# J7AEP_GPU_BXS464_WRAP0_GPU_SS_0_CORE_MMRS register map
Vendor: Texas Instruments
Peripheral module from a debugger description file (folder J7_AHP).
Registers are 64-bit, access per field, reset 0x0 unless marked. A register's access mark holds for its fields unless they carry their own. Offsets are as the file gives them; lines under a group give offsets from that group; [hi:lo] are bit positions; {n}, {i} and the like mark numbered series; 'fields as' and 'values as' point back to an identical list; <NAME> marks a mode.

## J7AEP_GPU_BXS464_WRAP0_GPU_SS_0_CORE_MMRS (part 1 of 4)
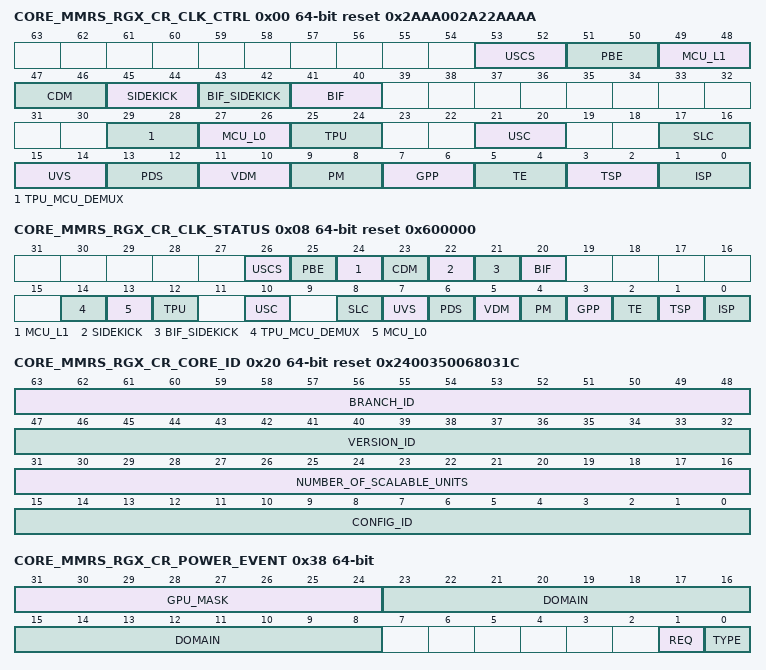
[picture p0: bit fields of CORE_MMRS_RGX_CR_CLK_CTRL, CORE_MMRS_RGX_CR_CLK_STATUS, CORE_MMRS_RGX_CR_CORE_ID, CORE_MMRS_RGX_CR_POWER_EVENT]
0x00 CORE_MMRS_RGX_CR_CLK_CTRL reset 0x2AAA002A22AAAA
  [53:52] USCS rw, [51:50] PBE rw, [49:48] MCU_L1 rw, [47:46] CDM rw, [45:44] SIDEKICK rw, [43:42] BIF_SIDEKICK rw, [41:40] BIF rw, [29:28] TPU_MCU_DEMUX rw, [27:26] MCU_L0 rw, [25:24] TPU rw, [21:20] USC rw, [17:16] SLC rw, [15:14] UVS rw, [13:12] PDS rw, [11:10] VDM rw, [9:8] PM rw, [7:6] GPP rw, [5:4] TE rw, [3:2] TSP rw, [1:0] ISP rw
0x08 CORE_MMRS_RGX_CR_CLK_STATUS ro reset 0x600000
  [26] USCS, [25] PBE, [24] MCU_L1, [23] CDM, [22] SIDEKICK, [21] BIF_SIDEKICK, [20] BIF, [14] TPU_MCU_DEMUX, [13] MCU_L0, [12] TPU, [10] USC, [8] SLC, [7] UVS, [6] PDS, [5] VDM, [4] PM, [3] GPP, [2] TE, [1] TSP, [0] ISP
0x18 CORE_MMRS_RGX_CR_PRODUCT_ID ro reset 0x8470000
  [31:16] IMG_PRODUCT_ID
0x20 CORE_MMRS_RGX_CR_CORE_ID ro reset 0x2400350068031C
  [63:48] BRANCH_ID — B - Branch ID
  [47:32] VERSION_ID — V - Version ID
  [31:16] NUMBER_OF_SCALABLE_UNITS — N - Number of scalable Units
  [15:0] CONFIG_ID — C - Config ID
0x28 CORE_MMRS_RGX_CR_CORE_IP_INTEGRATOR_ID ro
  [31:0] VALUE — IP company ID/Designer
0x30 CORE_MMRS_RGX_CR_CORE_IP_CHANGELIST ro
  [31:0] VALUE — Version control ID
0x38 CORE_MMRS_RGX_CR_POWER_EVENT
  [31:24] GPU_MASK rw — One bit per GPU indicating which GPUs are considered for the power event.
  [23:8] DOMAIN rw — sets which power island is enabled for the current power event request; bit0:jones, bit1-8:dusts, bit9-12:blackpearls
  [1] REQ rw — Set when a power event operation is requested
  [0] TYPE rw — The requested power event operation
0x50 CORE_MMRS_RGX_CR_DUSTS_ENABLE ro reset 0xFF
  [7:0] ENABLE — Dusts enabled
0x58 CORE_MMRS_RGX_CR_DUSTS_FUSE ro reset 0xFF
  [7:0] ENABLE — Dusts enabled
0x80 CORE_MMRS_RGX_CR_CLK_XTPLUS_CTRL reset 0x800000000
  [35:34] ASTC rw
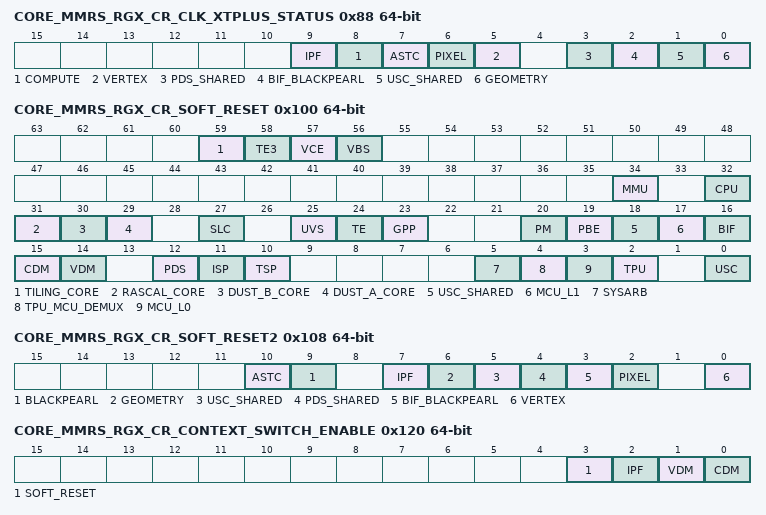
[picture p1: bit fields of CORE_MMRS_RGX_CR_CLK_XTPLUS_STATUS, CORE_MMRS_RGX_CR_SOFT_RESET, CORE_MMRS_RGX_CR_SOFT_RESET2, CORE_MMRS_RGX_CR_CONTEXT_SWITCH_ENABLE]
0x88 CORE_MMRS_RGX_CR_CLK_XTPLUS_STATUS ro
  [9] IPF, [8] COMPUTE, [7] ASTC, [6] PIXEL, [5] VERTEX, [3] PDS_SHARED, [2] BIF_BLACKPEARL, [1] USC_SHARED, [0] GEOMETRY
0xE0 CORE_MMRS_RGX_CR_SOC_TIMER_GRAY ro
  [63:0] VALUE
0xE8 CORE_MMRS_RGX_CR_SOC_TIMER_BINARY ro
  [63:0] VALUE
0x100 CORE_MMRS_RGX_CR_SOFT_RESET
  [59] TILING_CORE ro
  [58] TE3 ro
  [57] VCE ro
  [56] VBS ro
  [34] MMU rw
  [32] CPU rw — Includes MTS and META or MIPS
  [31] RASCAL_CORE rw — Note that the RASL_CORE bit affects logic related to the reading and writing of registers. This soft reset should therefore be used with caution. Upon power down events it is necessary to reset every register, so this bit should be used, but it must be release before any other resets, or beofre anyu other registers are programmed
  [30] DUST_B_CORE rw
  [29] DUST_A_CORE rw
  [27] SLC rw
  [25] UVS rw
  [24] TE rw
  [23] GPP rw
  [20] PM rw
  [19] PBE rw
  [18] USC_SHARED rw
  [17] MCU_L1 rw
  [16] BIF rw — Bifpmcache BIF
  [15] CDM rw
  [14] VDM rw
  [12] PDS rw
  [11] ISP rw
  [10] TSP rw
  [5] SYSARB rw
  [4] TPU_MCU_DEMUX rw
  [3] MCU_L0 rw
  [2] TPU rw
  [0] USC rw
0x108 CORE_MMRS_RGX_CR_SOFT_RESET2
  [10] ASTC rw, [9] BLACKPEARL ro, [7] IPF ro, [6] GEOMETRY ro, [5] USC_SHARED ro, [4] PDS_SHARED ro, [3] BIF_BLACKPEARL ro, [2] PIXEL ro, [0] VERTEX ro
0x120 CORE_MMRS_RGX_CR_CONTEXT_SWITCH_ENABLE
  [3] SOFT_RESET rw, [2] IPF rw, [1] VDM rw, [0] CDM rw
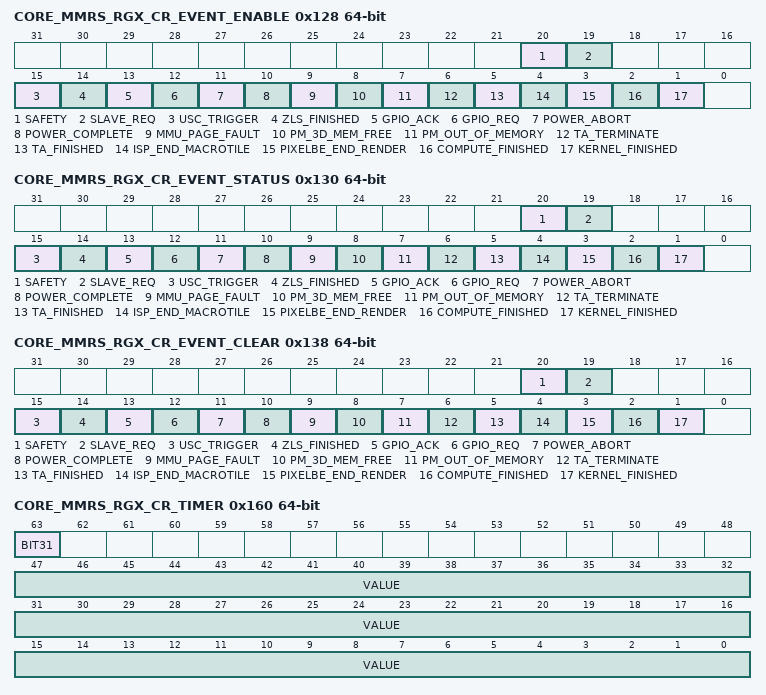
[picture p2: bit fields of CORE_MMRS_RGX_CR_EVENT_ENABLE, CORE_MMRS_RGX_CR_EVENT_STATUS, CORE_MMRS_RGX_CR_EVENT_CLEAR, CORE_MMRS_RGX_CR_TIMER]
0x128 CORE_MMRS_RGX_CR_EVENT_ENABLE
  [20] SAFETY rw — Indicates an interrupt event from an active safety feature has been received
  [19] SLAVE_REQ rw — Indicates an interrupt event from a slave has been received.
  [15] USC_TRIGGER rw — One or more USC has executed a nop.trigger instruction
  [14] ZLS_FINISHED rw — ZLS has finished all tiles in a Render
  [13] GPIO_ACK rw — General Purpose ouput acknowledgement
  [12] GPIO_REQ rw — General Purpose input request
  [11] POWER_ABORT rw — The requested power operation has been denied.
  [10] POWER_COMPLETE rw — The requested power operation has completed
  [9] MMU_PAGE_FAULT rw — An MMU page fault has occurred
  [8] PM_3D_MEM_FREE rw — PM memory allocation completed for the current render
  [7] PM_OUT_OF_MEMORY rw — PM memory allocation failed for a macro-tile
  [6] TA_TERMINATE rw — The TE has aborted a macro tile after a failted PM allocation request
  [5] TA_FINISHED rw — The TA phase has completed
  [4] ISP_END_MACROTILE rw — ISP End-of-Macrotile
  [3] PIXELBE_END_RENDER rw — The 3D phase has completed
  [2] COMPUTE_FINISHED rw — The compute phase has completed
  [1] KERNEL_FINISHED rw — A compute kernel has completed and updated the associated event object in external memory
0x130 CORE_MMRS_RGX_CR_EVENT_STATUS
  fields as CORE_MMRS_RGX_CR_EVENT_ENABLE
0x138 CORE_MMRS_RGX_CR_EVENT_CLEAR
  [20] SAFETY wo — Indicates an interrupt event from an active safety feature has been received
  [19] SLAVE_REQ wo — Indicates an interrupt event from a slave has been received.
  [15] USC_TRIGGER wo — One or more USC has executed a nop.trigger instruction
  [14] ZLS_FINISHED wo — ZLS has finished all tiles in a Render
  [13] GPIO_ACK wo — General Purpose ouput acknowledgement
  [12] GPIO_REQ wo — General Purpose input request
  [11] POWER_ABORT wo — The requested power operation has been denied.
  [10] POWER_COMPLETE wo — The requested power operation has completed
  [9] MMU_PAGE_FAULT wo — An MMU page fault has occurred
  [8] PM_3D_MEM_FREE wo — PM memory allocation completed for the current render
  [7] PM_OUT_OF_MEMORY wo — PM memory allocation failed for a macro-tile
  [6] TA_TERMINATE wo — The TE has aborted a macro tile after a failted PM allocation request
  [5] TA_FINISHED wo — The TA phase has completed
  [4] ISP_END_MACROTILE wo — ISP End-of-Macrotile
  [3] PIXELBE_END_RENDER wo — The 3D phase has completed
  [2] COMPUTE_FINISHED wo — The compute phase has completed
  [1] KERNEL_FINISHED wo — A compute kernel has completed and updated the associated event object in external memory
0x140 CORE_MMRS_RGX_CR_GPIO_OUTPUT_DATA
  [7:0] DATA rw — The data the firmware wants to transfer
0x148 CORE_MMRS_RGX_CR_GPIO_OUTPUT_REQ
  [0] REQ rw — Set when the firmware wants to communicate with a external HW
0x150 CORE_MMRS_RGX_CR_GPIO_INPUT_DATA ro
  [7:0] DATA — The incoming data from HW external to Rogue
0x158 CORE_MMRS_RGX_CR_GPIO_INPUT_ACK
  [0] ACK rw — Set by the firmware when it has acknowledged the incoming request
0x160 CORE_MMRS_RGX_CR_TIMER ro
  [63] BIT31, [47:0] VALUE
0x168 CORE_MMRS_RGX_CR_AXI_EXACCESS
  [0] SOCIF_ENABLE rw — enable the exclusive access logic in the socif img_axi2img. vhd module
0x190 CORE_MMRS_RGX_CR_PM_TASK_MLIST_LOAD
  [0] PENDING wo — A write to this register will cause the MLIST pointer to be loaded from either PM_MLIST0_START_OF or PM_MLIST1_START_OF, depending upon the Context ID contained in PM_CONTEXT_ID_MLS_LS. A read to this register return '1' until this operation has completed.
0x198 CORE_MMRS_RGX_CR_PM_TASK_MLIST_CLEAR
  [0] PENDING wo — A write to this register will cause the MLIST pointer to be reset to 0. A read to this register return '1' until this operation has completed.
0x1A0 CORE_MMRS_RGX_CR_PM_TA_MAX_RENDER_TARGET
  [10:0] ID rw — If used, the software should program this with the maximum render target array index used within the Scene
0x1A8 CORE_MMRS_RGX_CR_PM_MTILE_ARRAY_REORDER_VALID_STATUS ro
  [0] OP
0x1B0 CORE_MMRS_RGX_CR_PM_EMPTY_PAGE_FAST_FREEING reset 0x1
  [0] ID rw — When set, enable freeing of unused pages during TA phase
0x1B8 CORE_MMRS_RGX_CR_PM_MMU_REMAP_PENDING
  [0] OP wo — Pending status register corresponding to the MMU remapping operation, it will become '1' when written and deassert when the operation complete.
0x1C0 CORE_MMRS_RGX_CR_PM_PBE_FORCE_FREEING reset 0x1
  [0] ENABLE rw — When this bit is set, PM will free all the 3D context Memory when a genuine pixelbe end of render is received.
0x1C8 CORE_MMRS_RGX_CR_PM_PDS_STARTOF_MTILEFREE
  [16:0] OP rw — This startof register indicates the macrotile number of the PDSs current macrotile free request, needs to be programmed by FW on a render start
0x200 CORE_MMRS_RGX_CR_PM_TASK_3D_FREE_LOAD
  [0] PENDING wo — A write into this register will cause the 3D free list context to be loaded from the relevant configuration registers
0x208 CORE_MMRS_RGX_CR_PM_TASK_TA_FREE_LOAD
  [0] PENDING wo — A write into this register will cause the TA free list context to be loaded from the relevant configuration registers
0x210 CORE_MMRS_RGX_CR_PM_TA_FSTACK_BASE
  [39:4] ADDR rw — 1TB Addressable, 128 bits aligned Base Address for TA context page tables in the DPM module
0x218 CORE_MMRS_RGX_CR_PM_3D_FSTACK_BASE
  [39:4] ADDR rw — 1TB Addressable, 128 bits aligned Base Address for 3D context page tables in the DPM module
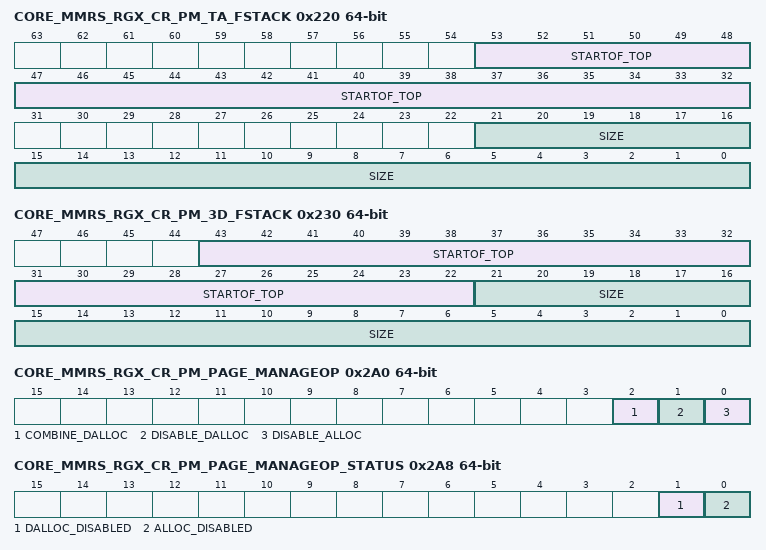
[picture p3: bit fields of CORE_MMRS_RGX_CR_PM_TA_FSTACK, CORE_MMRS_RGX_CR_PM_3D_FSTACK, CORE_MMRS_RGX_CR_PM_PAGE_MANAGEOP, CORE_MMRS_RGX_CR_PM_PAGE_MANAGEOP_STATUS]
0x220 CORE_MMRS_RGX_CR_PM_TA_FSTACK
  [53:32] STARTOF_TOP rw — This register defines the head pointer of the free list in terms of 4K free pages in the free list stack, effective on a load TA context.
  [21:0] SIZE rw — This register defines the number of 4K pages in the free list stack used for the TA page allocation, effective on a load TA context.
0x230 CORE_MMRS_RGX_CR_PM_3D_FSTACK
  [43:22] STARTOF_TOP rw — This register defines the head pointer of the free list in terms of 4K free pages in the free list stack, effective on a load TA context.
  [21:0] SIZE rw — This register defines the number of 4K pages in the free list stack used for the TA page allocation, effective on a load TA context.
0x240 CORE_MMRS_RGX_CR_PM_MTILE_ARRAY
  [39:4] BASE_ADDR rw — 1TB Addressable, 128 bits aligned Base Address for Mtile Array Base
0x248 CORE_MMRS_RGX_CR_PM_VHEAP_TABLE
  [39:4] BASE_ADDR rw — 1TB Addressable, 128 bits aligned Base Address for Virtual Heap Table
0x250 CORE_MMRS_RGX_CR_PM_TASK_VHEAP_LOAD
  [0] PENDING rw — Causes the vheap to be loaded as specified by the relevant configuration registers, when it is done the hw will clear this bit
0x258 CORE_MMRS_RGX_CR_PM_TASK_VHEAP_CLEAR
  [0] PENDING rw — Causes the vheap to be cleared as specified by the relevant configuration registers. When it is done, the hw will clear this bit
0x260 CORE_MMRS_RGX_CR_PM_TASK_VHEAP_STORE
  [0] PENDING rw — Causes the vheap to be stored as specified by the relevant configuration registers. When it is done, the hw will clear this bit
0x268 CORE_MMRS_RGX_CR_PM_ALIST0_START_OF
  [32:0] TAIL rw — allocation List 0 tail pointer
0x270 CORE_MMRS_RGX_CR_PM_ALIST0_STATUS ro
  [32:0] TAIL — allocation List tail pointer
0x278 CORE_MMRS_RGX_CR_PM_ALIST1_START_OF
  [32:0] TAIL rw — start of the allocation list tail pointer
0x280 CORE_MMRS_RGX_CR_PM_ALIST1_STATUS ro
  [32:0] TAIL — allocation List tail pointer
0x288 CORE_MMRS_RGX_CR_PM_TASK_ALIST_LOAD
  [0] PENDING wo — the write to this register will cause allocation list to be loaded from the relevant configuration registers
0x290 CORE_MMRS_RGX_CR_PM_TASK_ALIST_CLEAR
  [0] PENDING wo — the write to this register will causes the allocation list to be cleard from the relevant configuration registers
0x298 CORE_MMRS_RGX_CR_PM_DEALLOCATION_STARTOF_MASK
  [15:0] OP rw — This is the start of the mask PM deallocation will be based on. Normally, it is 0. However, in ISP context resume or extra 3D timeout case, the driver has to programme the value from the previous render.
0x2A0 CORE_MMRS_RGX_CR_PM_PAGE_MANAGEOP
  [2] COMBINE_DALLOC rw — 1 means the PM writes to the free stack will be burst combined
  [1] DISABLE_DALLOC rw — 1 means the PM page management deallocation operation will be disabled
  [0] DISABLE_ALLOC rw — 1 means the PM page management allocation operation will be disabled
0x2A8 CORE_MMRS_RGX_CR_PM_PAGE_MANAGEOP_STATUS ro
  [1] DALLOC_DISABLED — 1 means the PM page management operation has been disabled
  [0] ALLOC_DISABLED — 1 means the PM page management operation has been disabled
0x2B0 CORE_MMRS_RGX_CR_PM_CONTEXT_PB_BASE
  [2:0] CMP rw — Defines whether the TA/3D/HOST contexts are using the same parameter buffer. Setting a bit to '1' indicates that the context is using a different parameter buffer. Bit 0 = 0 : Unified Free List 3D context Parameter buffer = Unified Free List TA context Parameter buffer Bit 1 = 0 : 3D context parameter buffer = TA context parameter buffer Bit 2 = 0 : MMU Free List 3D context Parameter buffer = MMU Free List TA context Parameter buffer[this is a per context resource, so it should be the same with bit 1
0x2B8 CORE_MMRS_RGX_CR_PM_MLIST0_START_OF
  [21:0] TAIL rw — allocation List 0 tail pointer
0x2C0 CORE_MMRS_RGX_CR_PM_MLIST0_STATUS ro
  [21:0] TAIL — allocation List 1 tail pointer
0x2C8 CORE_MMRS_RGX_CR_PM_MLIST1_START_OF
  [21:0] TAIL rw — start of the allocation list 1 tail pointer
0x2D0 CORE_MMRS_RGX_CR_PM_MLIST1_STATUS ro
  [21:0] TAIL — mmu allocation List 1 tail pointer
0x2D8 CORE_MMRS_RGX_CR_PM_MLIST0_BASE
  [39:4] ADDR rw — 1TB Addressable, 128 bits aligned Base Address for mmu list0 module, Effective Immediately
0x2E0 CORE_MMRS_RGX_CR_PM_MLIST1_BASE
  [39:4] ADDR rw — 1TB Addressable, 128 bits aligned Base Address for mmu list1 module, Effective Immediately
0x2F8 CORE_MMRS_RGX_CR_PM_VCE_VTOP_STATUS ro
  [20:0] OP — Virtual Page Pointer for the VCE, 8KB granularity
0x300 CORE_MMRS_RGX_CR_PM_TE_VTOP_STATUS ro
  [20:0] OP — Virtual Page Pointer for the TE, 8KB granularity
0x308 CORE_MMRS_RGX_CR_PM_OUTOF_MEM_SRC ro
  [2:0] OP — one hot encoding indicating which part of resource runs out of memory bit 0: normal ta free list, bit 1: unified ta free list, bit 2: mmu free list
0x310 CORE_MMRS_RGX_CR_PM_ALIST_VTOP_STATUS ro
  [20:0] OP — Virtual Page Pointer for the allocation list, 8KB granularity
0x318 CORE_MMRS_RGX_CR_PM_MMU_VTOP_STATUS ro
  [20:0] OP — Virtual Page Pointer for the MMU, 4KB granularity
0x320 CORE_MMRS_RGX_CR_PM_OUTOFMEM_ABORTALL
  [0] OP wo — Instruct the PM to Deny the TE allocation outstanding on Out Of Memory
0x328 CORE_MMRS_RGX_CR_PM_OUTOFMEM_RESTART
  [0] OP wo — Restart the PM after an Out of Memory and Abort sequence
0x330 CORE_MMRS_RGX_CR_PM_REQUESTING_SOURCE ro
  [1:0] OP — Requesting source when out of memory. Bit 1 : VCE, Bit 0 : TE
0x338 CORE_MMRS_RGX_CR_PM_PARTIAL_RENDER_ENABLE
  [0] OP rw — Partial Render Enable Bit
0x340 CORE_MMRS_RGX_CR_PM_3D_DEALLOCATE_SCANMODE
  [4:0] OP rw — This register defines the deallocation behaviour of the PM: value > 2 is only for debug, on ZLS mode 0, it can only set less than 2 0: PM will free the macrotile memory as soon as it is possible 1: PM only free one mtile for each traverse 2: PM only free two mtiles for each traverse ... 16: PM only free 16 mtiles for each traverse. Other Value are all invalid values
0x348 CORE_MMRS_RGX_CR_PM_TA_FSTACK_STATUS ro
  [21:0] TOP — This status register indicated the ta context free list pointer status.
0x350 CORE_MMRS_RGX_CR_PM_3D_FSTACK_STATUS ro
  [21:0] TOP — This status register indicated the 3D context free list status
0x358 CORE_MMRS_RGX_CR_PM_RESERVE_PAGES reset 0x5
  [15:0] OP rw — This register defines the guard page required for one VCE/TE allocation. The requirement is set by the number of ppages needed to create the ALIST nodes when a vpage is closed. The MMU requirement is fixed at 3 ppages max for creatig a new ALIST mapping. The rest of the guarding is formed of the amount of ALIST space needed to form the maximum number of nodes a vpage could need. This is defined by the number of RTAs that could be present in a vpage. In all cores, the amount of ALIST space needed doesn't exceed 1 ppage. However the ALIST is allocated at vpage granularity so this needs to be rounded up to a vpage size in ppages. With a vpage size of 16KB or 4*4KB the requirement is 4 ppages and the TOTAL = 3+4 meaning a register setting of 0x7 is required. With a vpage size of 8KB or 2*4Kb the requirement is 2 ppages and the TOTAL = 3+2 meaning a register setting of 0x5 is required.
0x360 CORE_MMRS_RGX_CR_PM_DEALLOCATED_MASK_STATUS ro
  [15:0] TOP — This status register contains a bitmask of the macrotiles freed at this point in the render
0x368 CORE_MMRS_RGX_CR_PM_DEALLOCATING_MASK_STATUS ro
  [15:0] TOP — This status register indicates the mtile mask being freed at the current traverse
0x370 CORE_MMRS_RGX_CR_PM_PDS_MTILEFREE_STATUS ro
  [16:0] OP — This status register indicates the macrotile number of the PDSs current macrotile free request
0x378 CORE_MMRS_RGX_CR_PM_TA_FREE_CONTEXT
  [0] PENDING rw — free the ta context register operation
0x380 CORE_MMRS_RGX_CR_PM_3D_TIMEOUT_NOW
  [0] OP wo — free the 3D context
0x388 CORE_MMRS_RGX_CR_PM_3D_DEALLOCATE_ENABLE reset 0x1
  [0] OP rw — 3D deallocate enable mode
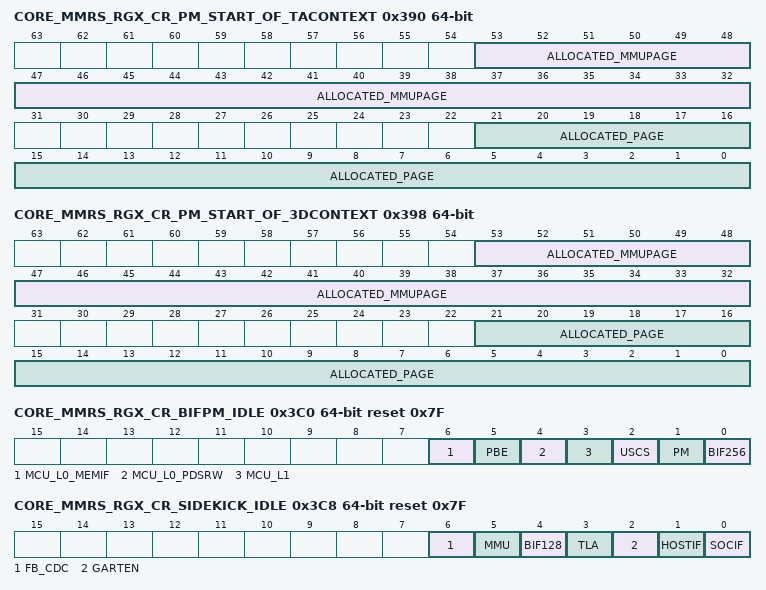
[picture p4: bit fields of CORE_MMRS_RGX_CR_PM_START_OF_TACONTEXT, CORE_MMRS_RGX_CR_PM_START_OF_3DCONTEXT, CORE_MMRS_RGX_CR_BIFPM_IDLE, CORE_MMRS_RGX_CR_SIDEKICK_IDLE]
0x390 CORE_MMRS_RGX_CR_PM_START_OF_TACONTEXT
  [53:32] ALLOCATED_MMUPAGE rw — Start of TA MMU pages[4KB] on loading of the TA context
  [21:0] ALLOCATED_PAGE rw — Start of TA pages[4KB] on loading of the TA context
0x398 CORE_MMRS_RGX_CR_PM_START_OF_3DCONTEXT
  [53:32] ALLOCATED_MMUPAGE rw — Start of 3D MMU pages[4KB] on loading of the TA context
  [21:0] ALLOCATED_PAGE rw — Start of 3D pages[4KB] on loading of the TA context
0x3A0 CORE_MMRS_RGX_CR_PM_TA_PAGE_STATUS ro
  [21:0] OP — The number of TA pages currently allocated
0x3A8 CORE_MMRS_RGX_CR_PM_3D_PAGE_STATUS ro
  [21:0] OP — The number of 3D pages currently allocated
0x3B0 CORE_MMRS_RGX_CR_PM_VCE_INFLIGHT_STATUS ro
  [20:0] OP — The Virtual Page Number in flight in the VCE Requestor
0x3B8 CORE_MMRS_RGX_CR_PM_TE_INFLIGHT_STATUS ro
  [20:0] OP — The Virtual Page Number in flight in the TE Requestor
0x3C0 CORE_MMRS_RGX_CR_BIFPM_IDLE ro reset 0x7F
  [6] MCU_L0_MEMIF — MCU L0 MEMIF Module IDLE
  [5] PBE — PBE Module IDLE
  [4] MCU_L0_PDSRW — MCU L0 PDSRW Module IDLE
  [3] MCU_L1 — MCU L1 Module IDLE
  [2] USCS — USC Shared Module IDLE
  [1] PM — PM Module IDLE
  [0] BIF256 — BIF256 Module IDLE
0x3C8 CORE_MMRS_RGX_CR_SIDEKICK_IDLE ro reset 0x7F
  [6] FB_CDC — FB CDC Module IDLE
  [5] MMU — MMU Module IDLE
  [4] BIF128 — BIF128 Module IDLE
  [3] TLA — TLA Module IDLE
  [2] GARTEN — GARTEN Module IDLE
  [1] HOSTIF — HOSTIF Module IDLE
  [0] SOCIF — SOCIF Module IDLE
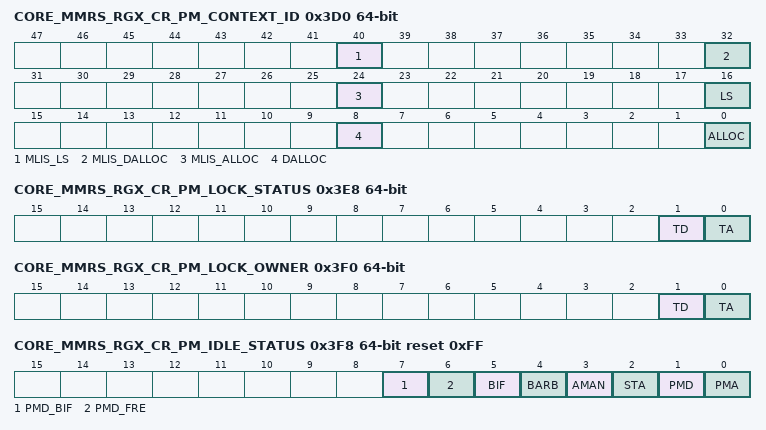
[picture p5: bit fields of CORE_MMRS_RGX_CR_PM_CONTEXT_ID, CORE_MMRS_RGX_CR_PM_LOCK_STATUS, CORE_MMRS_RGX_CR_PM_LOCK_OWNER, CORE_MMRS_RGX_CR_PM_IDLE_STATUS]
0x3D0 CORE_MMRS_RGX_CR_PM_CONTEXT_ID
  [40] MLIS_LS rw — MMU page List [TE,VCE aligned with this context ]Load Store Context ID
  [32] MLIS_DALLOC rw — MMU page List [TE,VCE aligned with this context ]DeAllocation Context ID
  [24] MLIS_ALLOC rw — MMU page List [TE,VCE aligned with this context ]Allocation Context ID
  [16] LS rw — Load Store Context ID for the allocation list
  [8] DALLOC rw — DeAllocation Context ID for the allocation list
  [0] ALLOC rw — Allocation Context ID for the allocation list
0x3D8 CORE_MMRS_RGX_CR_PM_3D_RENDER_TARGET_INDEX
  [10:0] ID rw — Render Target ID which is being rendered
0x3E0 CORE_MMRS_RGX_CR_PM_3D_RENDER_TARGET_LAST reset 0x1
  [0] ID rw — If this bit is set, this means the render will be the last one in the whole render target array. If no multiple render target array is present, this bit always needs set
0x3E8 CORE_MMRS_RGX_CR_PM_LOCK_STATUS ro
  [1] TD — Bit 1: 3D free list Lock Status. 0 idle/ 1 used
  [0] TA — Bit 0: TA free list Lock Status. 0 idle/ 1 used.
0x3F0 CORE_MMRS_RGX_CR_PM_LOCK_OWNER ro
  [1] TD — Bit 1 :3D free list Lock owner. 0 PMA / 1 PMD
  [0] TA — Bit 0: TA free list Lock Owner. 0 PMA / 1 PMD.
0x3F8 CORE_MMRS_RGX_CR_PM_IDLE_STATUS ro reset 0xFF
  [7] PMD_BIF — Idle Status Register of the PMD module bif state machine
  [6] PMD_FRE — Idle Status Register of the PMD module master state machine
  [5] BIF — Idle Status Register of the BIF Interface, default
  [4] BARB — Idle Status Register of the BIF Arbiter state BAR
  [3] AMAN — Idle Status Register of the Alist state machine
  [2] STA — Idle Status Register of the Stack Manager Modul
  [1] PMD — Idle Status Register of the PMD module
  [0] PMA — Idle Status Register of the PMA module
0x400 CORE_MMRS_RGX_CR_VDM_START
  [0] PULSE wo — Start VDM
0x408 CORE_MMRS_RGX_CR_VDM_CTRL_STREAM_BASE
  [39:2] ADDR rw — 1TB range, 32-bit aligned base address
0x410 CORE_MMRS_RGX_CR_VDM_CTRL_STREAM_CURRENT ro
  [39:2] ADDR — 1TB range, 32-bit aligned address
0x418 CORE_MMRS_RGX_CR_VDM_CALL_STACK_POINTER
  [39:3] ADDR rw — 1TB range, 64-bit aligned base address
0x420 CORE_MMRS_RGX_CR_VDM_BATCH
  [13:0] NUMBER rw
0x428 CORE_MMRS_RGX_CR_VDM_CONTEXT_STATE_BASE
  [39:4] ADDR rw — 1TB range, 128-bit aligned base address
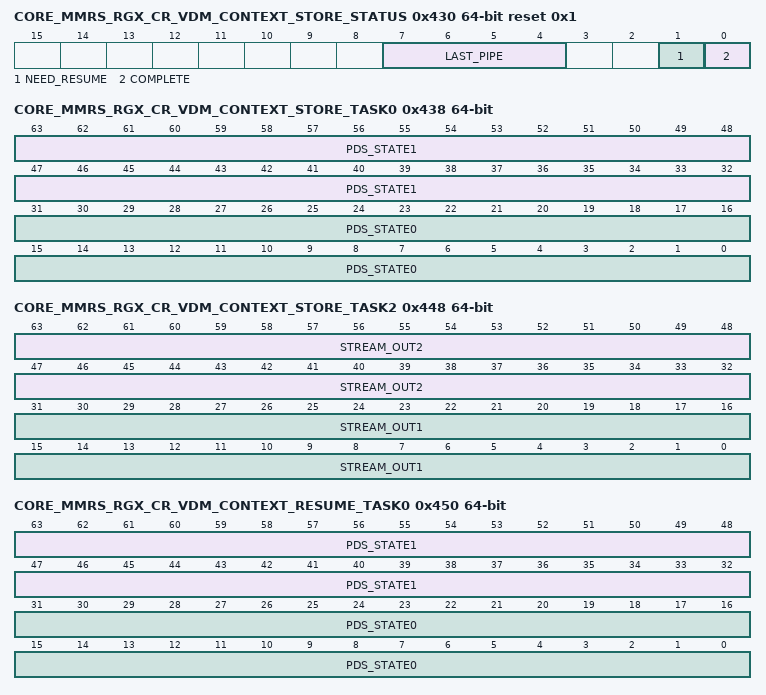
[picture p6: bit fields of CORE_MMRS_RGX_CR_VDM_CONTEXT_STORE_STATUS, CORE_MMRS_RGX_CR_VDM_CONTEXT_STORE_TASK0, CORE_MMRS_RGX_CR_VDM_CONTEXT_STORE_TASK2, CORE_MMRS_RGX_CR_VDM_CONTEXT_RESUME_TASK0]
0x430 CORE_MMRS_RGX_CR_VDM_CONTEXT_STORE_STATUS ro reset 0x1
  [7:4] LAST_PIPE — The TA pipe number to which the VDM last sent indices
  [1] NEED_RESUME — The VDM still has control stream left to process, meaning this context must be resumed
  [0] COMPLETE — The VDM has completed the context store operation and fenced its state to external memory
0x438 CORE_MMRS_RGX_CR_VDM_CONTEXT_STORE_TASK0 rw
  [63:32] PDS_STATE1, [31:0] PDS_STATE0
0x440 CORE_MMRS_RGX_CR_VDM_CONTEXT_STORE_TASK1
  [31:0] PDS_STATE2 rw
0x448 CORE_MMRS_RGX_CR_VDM_CONTEXT_STORE_TASK2 rw
  [63:32] STREAM_OUT2, [31:0] STREAM_OUT1
0x450 CORE_MMRS_RGX_CR_VDM_CONTEXT_RESUME_TASK0 rw
  [63:32] PDS_STATE1, [31:0] PDS_STATE0
0x458 CORE_MMRS_RGX_CR_VDM_CONTEXT_RESUME_TASK1
  [31:0] PDS_STATE2 rw
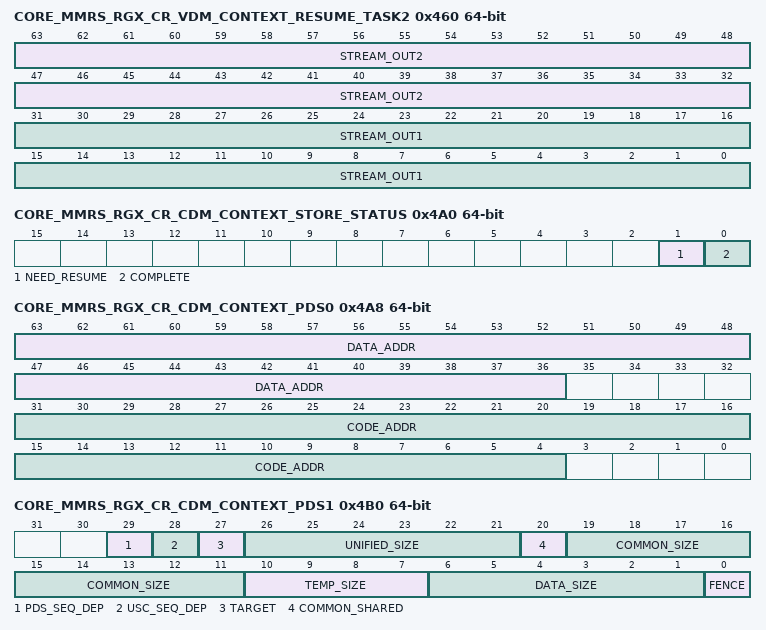
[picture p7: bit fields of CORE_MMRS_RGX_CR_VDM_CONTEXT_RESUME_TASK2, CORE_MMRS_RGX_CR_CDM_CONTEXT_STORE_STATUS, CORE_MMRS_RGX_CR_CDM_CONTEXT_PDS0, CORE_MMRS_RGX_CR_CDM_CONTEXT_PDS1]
0x460 CORE_MMRS_RGX_CR_VDM_CONTEXT_RESUME_TASK2 rw
  [63:32] STREAM_OUT2, [31:0] STREAM_OUT1
0x468 CORE_MMRS_RGX_CR_VDM_CONTEXT_STORE_START
  [0] PULSE wo
0x470 CORE_MMRS_RGX_CR_VDM_SYNC_PDS_DATA_BASE
  [31:4] ADDR rw
0x478 CORE_MMRS_RGX_CR_CDM_START
  [0] PULSE wo — Start CDM
0x480 CORE_MMRS_RGX_CR_CDM_CTRL_STREAM_BASE
  [39:2] ADDR rw — 1TB range, 32-bit aligned base address
0x488 CORE_MMRS_RGX_CR_CDM_CONTEXT_STORE
  [0] PULSE wo
0x490 CORE_MMRS_RGX_CR_CDM_CONTEXT_LOAD
  [0] PENDING wo
0x498 CORE_MMRS_RGX_CR_CDM_CONTEXT_STATE_BASE
  [39:4] ADDR rw — 1TB range, 128-bit aligned base address
0x4A0 CORE_MMRS_RGX_CR_CDM_CONTEXT_STORE_STATUS ro
  [1] NEED_RESUME — The CDM still has control stream left to process, meaning this context must be resumed
  [0] COMPLETE — The CDM has completed the context store operation and fenced its state to external memory
0x4A8 CORE_MMRS_RGX_CR_CDM_CONTEXT_PDS0
  [63:36] DATA_ADDR rw — PDS Data Address for Store/Load Program, 128-bit aligned
  [31:4] CODE_ADDR rw — PDS Code Address for Store/Load Program, 128-bit aligned
0x4B0 CORE_MMRS_RGX_CR_CDM_CONTEXT_PDS1
  [29] PDS_SEQ_DEP rw — PDS Sequential Dependency
  [28] USC_SEQ_DEP rw — USC Sequential Dependency
  [27] TARGET rw — USC Target [0=All, 1=Any]
  [26:21] UNIFIED_SIZE rw
  [20] COMMON_SHARED rw — PDS Common Store Allocation is Shared Registers
  [19:11] COMMON_SIZE rw — PDS Common Size
  [10:7] TEMP_SIZE rw — PDS Temp Size
  [6:1] DATA_SIZE rw — PDS Data Size
  [0] FENCE rw — Fence the Task in the PDS/USC - Set on Store, unset on Load
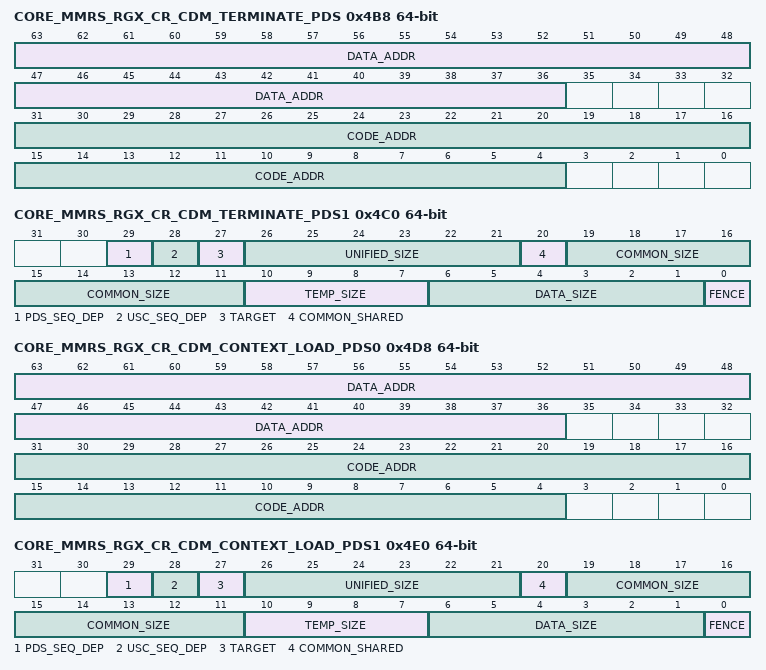
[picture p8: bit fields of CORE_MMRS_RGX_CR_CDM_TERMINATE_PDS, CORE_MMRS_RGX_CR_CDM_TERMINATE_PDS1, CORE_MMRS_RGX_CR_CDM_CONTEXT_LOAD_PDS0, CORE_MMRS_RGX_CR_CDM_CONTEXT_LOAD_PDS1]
0x4B8 CORE_MMRS_RGX_CR_CDM_TERMINATE_PDS
  [63:36] DATA_ADDR rw — PDS Data Address for Terminate Program, 128-bit aligned
  [31:4] CODE_ADDR rw — PDS Code Address for Terminate Program, 128-bit aligned
0x4C0 CORE_MMRS_RGX_CR_CDM_TERMINATE_PDS1
  [29] PDS_SEQ_DEP rw — PDS Sequential Dependency
  [28] USC_SEQ_DEP rw — USC Sequential Dependency
  [27] TARGET rw — USC Target [0=All, 1=Any]
  [26:21] UNIFIED_SIZE rw
  [20] COMMON_SHARED rw — PDS Common Store Allocation is Shared Registers
  [19:11] COMMON_SIZE rw — PDS Common Size
  [10:7] TEMP_SIZE rw — PDS Temp Size
  [6:1] DATA_SIZE rw — PDS Data Size
  [0] FENCE rw — Fence the Task in the PDS/USC - Set on Store Terminate
0x4D8 CORE_MMRS_RGX_CR_CDM_CONTEXT_LOAD_PDS0
  fields as CORE_MMRS_RGX_CR_CDM_CONTEXT_PDS0
0x4E0 CORE_MMRS_RGX_CR_CDM_CONTEXT_LOAD_PDS1
  fields as CORE_MMRS_RGX_CR_CDM_CONTEXT_PDS1
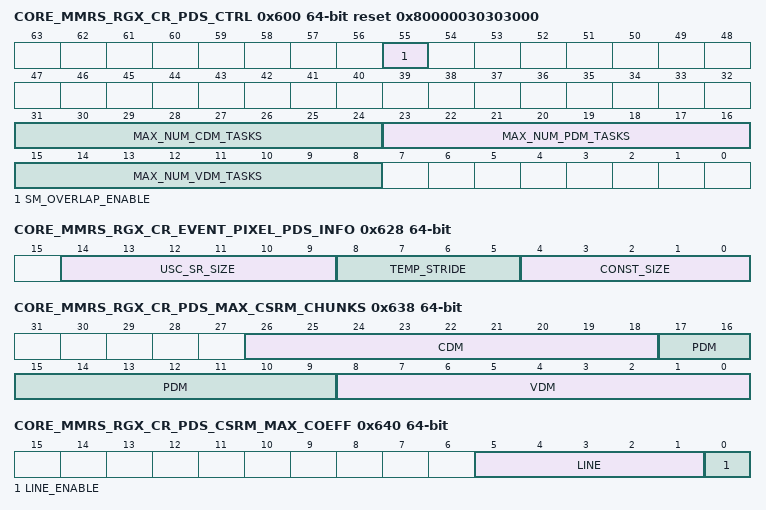
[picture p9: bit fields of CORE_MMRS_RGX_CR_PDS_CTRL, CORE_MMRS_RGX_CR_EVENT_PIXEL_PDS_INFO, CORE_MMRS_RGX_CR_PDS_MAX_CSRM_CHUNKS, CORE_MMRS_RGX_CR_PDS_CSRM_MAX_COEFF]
0x600 CORE_MMRS_RGX_CR_PDS_CTRL reset 0x80000030303000
  [55] SM_OVERLAP_ENABLE rw — Enable per Data Master slot tracking within the PDS Slot Manager [SM] for improved performance while running overlapped
  [31:24] MAX_NUM_CDM_TASKS rw — The maximum number of compute tasks allowed on each USC, range 0 to 48
  [23:16] MAX_NUM_PDM_TASKS rw — The maximum number of pixel tasks allowed on each USC, range 0 to 48
  [15:8] MAX_NUM_VDM_TASKS rw — The maximum number of vertex tasks [VS, HS, GS when Tess not enabled] allowed on each USC, range 0 to 39 [Note reduced range to prevent Pixel/VDM system deadlock]
0x608 CORE_MMRS_RGX_CR_PDS_USC_COLLATOR
  [0] CLEAR wo — Clear PDS Unified Clusters Resource Collator
0x610 CORE_MMRS_RGX_CR_PDS_EXEC_BASE
  [39:20] ADDR rw — 1TB addressable, 1 MB aligned base address for PDS programs
0x618 CORE_MMRS_RGX_CR_EVENT_PIXEL_PDS_CODE
  [31:4] ADDR rw — PDS Execution Address for pixel tasks [Positioned as a byte address, 128 bit granularity], 4 GB Range
0x620 CORE_MMRS_RGX_CR_EVENT_PIXEL_PDS_DATA
  fields as CORE_MMRS_RGX_CR_EVENT_PIXEL_PDS_CODE
0x628 CORE_MMRS_RGX_CR_EVENT_PIXEL_PDS_INFO
  [14:9] USC_SR_SIZE rw — USC Shared Register Data Size in 4x128 bit words [0=0] for pixel event task, if zero pixel event task is skipped
  [8:5] TEMP_STRIDE rw — PDS Temp Size in 128 bit words [0=0] for pixel event tasks
  [4:0] CONST_SIZE rw — PDS Data Size in 128 bit words [0=0] for pixel event tasks, if zero pixel event task is skipped
0x630 CORE_MMRS_RGX_CR_PDS_CSRM
  [0] CLEAR wo — Clear PDS Common Store Resource Manager, a write to this register results in a one cycle pulse
0x638 CORE_MMRS_RGX_CR_PDS_MAX_CSRM_CHUNKS
  [26:18] CDM rw — Max Number of Allocation Regions to Allocate to the Compute Data Master in Common Store
  [17:9] PDM rw — Max Number of Allocation Regions to Allocate to the Pixel Data Master in Common Store
  [8:0] VDM rw — Max Number of Allocation Regions to Allocate to the VDM Data Master in Common Store
0x640 CORE_MMRS_RGX_CR_PDS_CSRM_MAX_COEFF
  [5:1] LINE rw — Coefficients are allocated from Line 0 upwards, this is the maximum Line to use for Coefficients before wrapping
  [0] LINE_ENABLE rw — Enable Max Coefficient Line Limit
0x648 CORE_MMRS_RGX_CR_PDS_USRM
  [0] CLEAR wo — Clear PDS Unified Store Resource Manager, a write to this register results in a one cycle pulse
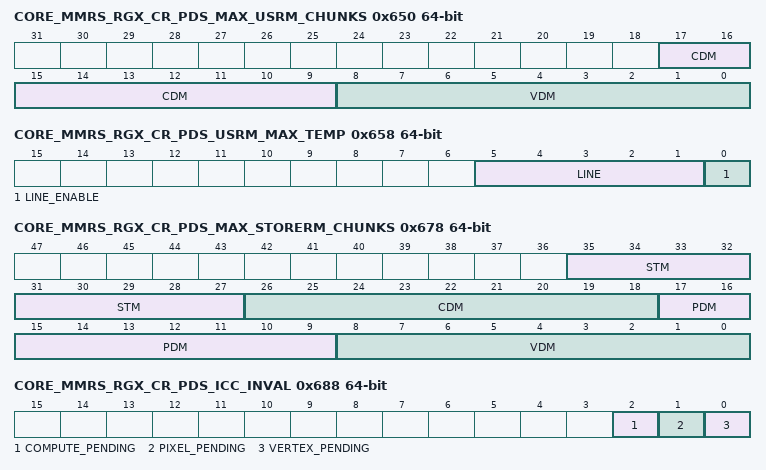
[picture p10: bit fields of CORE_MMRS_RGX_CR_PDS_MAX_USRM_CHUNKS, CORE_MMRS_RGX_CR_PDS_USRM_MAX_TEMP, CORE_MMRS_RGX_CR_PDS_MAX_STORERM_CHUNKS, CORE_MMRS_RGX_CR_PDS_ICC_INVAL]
0x650 CORE_MMRS_RGX_CR_PDS_MAX_USRM_CHUNKS
  [17:9] CDM rw — Max Number of Allocation Regions to Allocate to the Compute Data Master in Unified Store
  [8:0] VDM rw — Max Number of Allocation Regions to Allocate to the VDM Data Master in Unified Store
0x658 CORE_MMRS_RGX_CR_PDS_USRM_MAX_TEMP
  [5:1] LINE rw — Max Line for use as Temporaries
  [0] LINE_ENABLE rw — Enable Max Temporaries Line Limit
0x660 CORE_MMRS_RGX_CR_PDS_UVSRM
  [0] CLEAR wo — Clear PDS Unified Vertex Store Resource Manager, a write to this register results in a one cycle pulse
0x670 CORE_MMRS_RGX_CR_PDS_STORERM
  [0] CLEAR wo — Clear PDS Store Resource Manager, a write to this register results in a one cycle pulse
0x678 CORE_MMRS_RGX_CR_PDS_MAX_STORERM_CHUNKS
  [35:27] STM rw — Max Number of Allocation Regions to Allocate to the Stream Out Data Master in PDS Store
  [26:18] CDM rw — Max Number of Allocation Regions to Allocate to the Compute Data Master in PDS Store
  [17:9] PDM rw — Max Number of Allocation Regions to Allocate to the Pixel Data Master in PDS Store
  [8:0] VDM rw — Max Number of Allocation Regions to Allocate to the VDM Data Master in PDS Store
0x688 CORE_MMRS_RGX_CR_PDS_ICC_INVAL
  [2] COMPUTE_PENDING wo — PDS Instruction Cache Compute [DM 2] has been invalidated
  [1] PIXEL_PENDING wo — PDS Instruction Cache Pixel [DM 1] has been invalidated
  [0] VERTEX_PENDING wo — PDS Instruction Cache Vertex [DM 0] has been invalidated
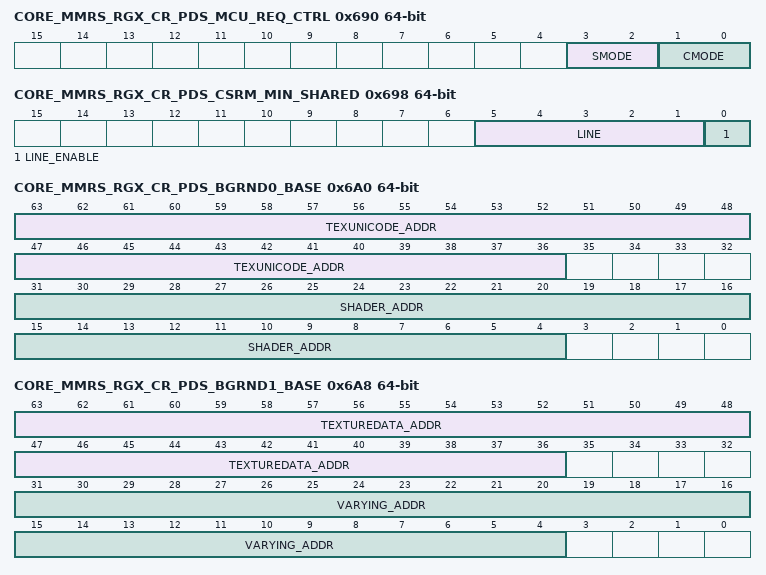
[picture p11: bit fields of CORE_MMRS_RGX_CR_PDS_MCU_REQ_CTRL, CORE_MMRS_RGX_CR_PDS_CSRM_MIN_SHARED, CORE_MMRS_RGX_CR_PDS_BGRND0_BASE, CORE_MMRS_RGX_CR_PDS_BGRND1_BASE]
0x690 CORE_MMRS_RGX_CR_PDS_MCU_REQ_CTRL
  [3:2] SMODE rw — SLC cache policy to use for requests from the VDM/PDM/CDM/STM resource requestors inside the PDS
  [1:0] CMODE rw — Cache Mode to use for requests from the VDM/PDM/CDM/STM resource requestors inside the PDS
0x698 CORE_MMRS_RGX_CR_PDS_CSRM_MIN_SHARED
  [5:1] LINE rw — Shared are allocated from top line downwards, this is the minimum Line to use for Shared Registers before wrapping
  [0] LINE_ENABLE rw — Enable Min Shared Register Line Limit
0x6A0 CORE_MMRS_RGX_CR_PDS_BGRND0_BASE
  [63:36] TEXUNICODE_ADDR rw — This is the PDS Code Address used for 2 programs. The Program which issues the DMAs [DOUTD etc. ] for uniform data and/or texture state.
  [31:4] SHADER_ADDR rw — The pixel shader base is the base address of the PDS Data Segment. The code segment is address is PDS_PIXEL_SHADERBASE + PDS_PIXELSHADERSIZE. The pixel shader program issues the DOUTU for the Fragment Shader only.
0x6A8 CORE_MMRS_RGX_CR_PDS_BGRND1_BASE
  [63:36] TEXTUREDATA_ADDR rw — This points to the DMAs to load the Texture State [or contains the State with DOUTW commands]
  [31:4] VARYING_ADDR rw — This is the base address of the PDS Data Segment. The code segment is address is PDS_VARYINGBASE + PDS_VARYINGSIZE [PDS_BGRND_SIZEINFO1].
0x6B0 CORE_MMRS_RGX_CR_PDS_BGRND2_BASE
  [31:4] UNIFORMDATA_ADDR rw — This points to the DMAs to load the Uniforms [or contains the Uniforms with DOUTW commands]
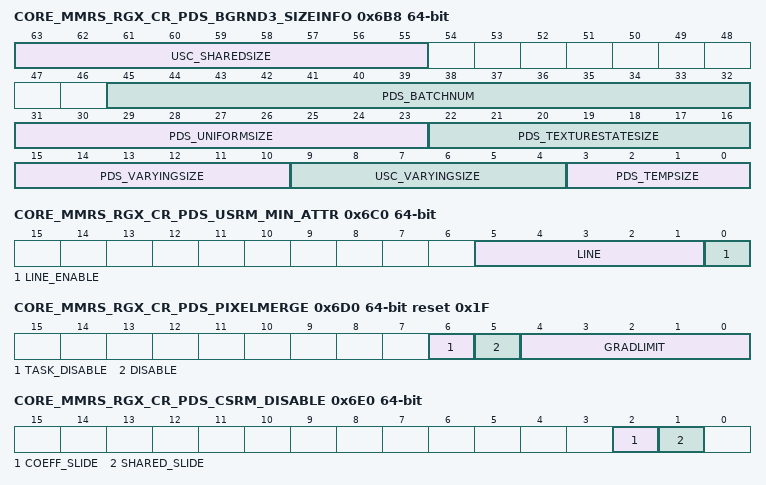
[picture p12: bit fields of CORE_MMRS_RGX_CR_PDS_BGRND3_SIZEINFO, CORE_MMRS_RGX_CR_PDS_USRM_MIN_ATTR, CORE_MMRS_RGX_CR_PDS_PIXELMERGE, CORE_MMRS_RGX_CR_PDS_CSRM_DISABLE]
0x6B8 CORE_MMRS_RGX_CR_PDS_BGRND3_SIZEINFO
  [63:55] USC_SHAREDSIZE rw — The common store allocation size for the shared registers [texture and uniform data commbined]
  [45:32] PDS_BATCHNUM rw — The batch ID to be associated with the background
  [31:23] PDS_UNIFORMSIZE rw — The size of the Uniform PDS Data Segment in 128 bit words
  [22:16] PDS_TEXTURESTATESIZE rw — The size of the Texture PDS Data Segment in 128 bit words
  [15:10] PDS_VARYINGSIZE rw — The size of the Varying/Coefficient PDS Data Segment in 128 bit words
  [9:4] USC_VARYINGSIZE rw — The size of the Varying/Coefficient USC Common Store Data in 4x128 bit words
  [3:0] PDS_TEMPSIZE rw — 0 = 0 128 bit words, 1 = 1 128 bit word, this applies to coefficient, uniform and varying state
0x6C0 CORE_MMRS_RGX_CR_PDS_USRM_MIN_ATTR
  [5:1] LINE rw — Min Line for use for Attributes
  [0] LINE_ENABLE rw — Enable Min Attributes Line Limit
0x6D0 CORE_MMRS_RGX_CR_PDS_PIXELMERGE reset 0x1F
  [6] TASK_DISABLE rw — Disable pixel merging within a whole pixel fragment task
  [5] DISABLE rw — Disable pixel merging within each 2x2 pixel block of a pixel fragment task
  [4:0] GRADLIMIT rw — Gradient difference limit for PDS PP pixel merging
0x6D8 CORE_MMRS_RGX_CR_PDS_CSRM_USC_DEBUG
  [4:0] SIZE rw — Amount of Space [in 512-bit Allocation Regions] to allocate to USC Debug Space on a Shared Allocation.
0x6E0 CORE_MMRS_RGX_CR_PDS_CSRM_DISABLE
  [2] COEFF_SLIDE rw — Disable Slide of Coeff Allocations on Failure
  [1] SHARED_SLIDE rw — Disable Slide of Shared Allocations on Failure
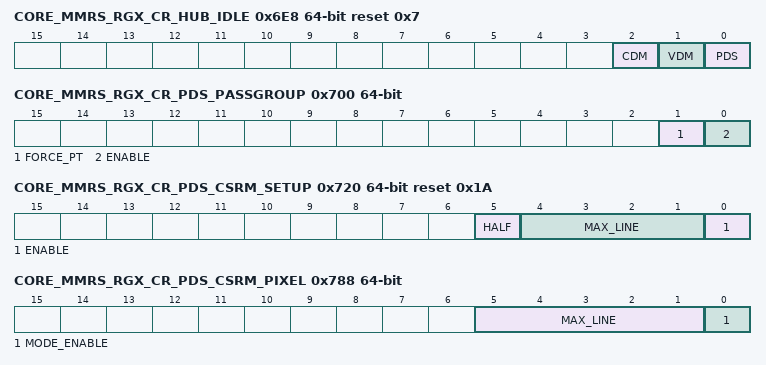
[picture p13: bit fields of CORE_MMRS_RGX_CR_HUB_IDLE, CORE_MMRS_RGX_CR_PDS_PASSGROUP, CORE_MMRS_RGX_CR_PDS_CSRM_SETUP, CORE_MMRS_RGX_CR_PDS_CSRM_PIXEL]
0x6E8 CORE_MMRS_RGX_CR_HUB_IDLE ro reset 0x7
  [2] CDM — CDM Module IDLE
  [1] VDM — VDM Module IDLE
  [0] PDS — PDS Module IDLE
0x6F0 CORE_MMRS_RGX_CR_HUB_PWR ro
  [31:0] NUM_PDS_INST — Number of PDS instructions
0x700 CORE_MMRS_RGX_CR_PDS_PASSGROUP
  [1] FORCE_PT rw — Force the use of Hard SDs between punchthrough or depth feedback type passes
  [0] ENABLE rw — Enable pass group optimisation within USC by replacing USC Hard SDs with USC Soft SDs for all pass groups in the PDS PP.
0x708 CORE_MMRS_RGX_CR_PDS_COMPUTE_THREAD_BARRIER
  [0] ENABLE rw — Enable thread barrier support in the PDS CDM_RR.
0x720 CORE_MMRS_RGX_CR_PDS_CSRM_SETUP reset 0x1A
  [5] HALF rw — Top line is prefilled half full
  [4:1] MAX_LINE rw — [Lower 4 bits of] Maximum Line within the CSRM that can be allocated to Shared Registers/Coefficients
  [0] ENABLE rw — Enable use of this register to set the Maximum Line the CSRM can allocate on behalf of the USC Common Store
0x738 CORE_MMRS_RGX_CR_PDS_USRM_DISABLE
  [0] TEMP_SLIDE rw — Disable Slide of Temp Allocations on Failure
0x788 CORE_MMRS_RGX_CR_PDS_CSRM_PIXEL
  [5:1] MAX_LINE rw — Coefficients are allocated from Line 0 upwards, this is the maximum Line to reserve for ONLY PDM Coefficients. The Max line of this region is set in the PDS_CSRM_MAX_COEFF register
  [0] MODE_ENABLE rw — Enable PIXEL RESERVE MODE in the PDS CSRM
0x890 CORE_MMRS_RGX_CR_XPU_BROADCAST reset 0x1
  [8:0] MASK rw — If bit N is set, forward broadcast XPU register writes to this device.
0x898 CORE_MMRS_RGX_CR_XPU_RW_ORDER reset 0x1
  [0] FORCE rw — 1 - Force reads and writes to complete in order with respect to each other on the XPU register AXI bus by stalling read requests if any writes are outstanding and vice versa. 0 - No ordering is enforced between reads and writes. Writes and reads complete in order with respect to themselves as dictated by AXI ID constraints.
0x8F0 CORE_MMRS_RGX_CR_SLAVE_EVENT ro
  [7:0] STATUS — If bit N is set, an interrupt from slave N is pending.
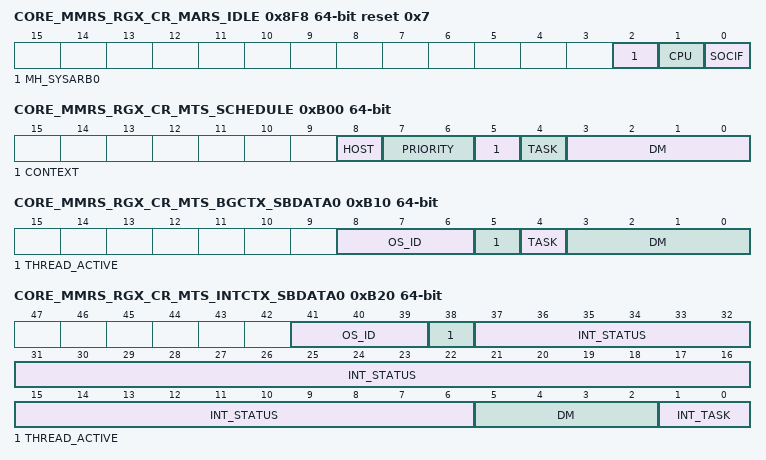
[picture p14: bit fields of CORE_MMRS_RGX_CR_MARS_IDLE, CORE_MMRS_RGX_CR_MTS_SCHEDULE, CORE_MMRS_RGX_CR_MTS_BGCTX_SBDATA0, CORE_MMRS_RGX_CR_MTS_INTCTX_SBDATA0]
0x8F8 CORE_MMRS_RGX_CR_MARS_IDLE ro reset 0x7
  [2] MH_SYSARB0 — SYSARB0 Module IDLE
  [1] CPU — CPU Module IDLE
  [0] SOCIF — SOCIF Module IDLE
0xB00 CORE_MMRS_RGX_CR_MTS_SCHEDULE
  [8] HOST wo — Host Interrupte kick
  [7:6] PRIORITY wo — DataMaster Priority
  [5] CONTEXT wo
  [4] TASK wo
  [3:0] DM wo — DataMaster Type
0xB08 CORE_MMRS_RGX_CR_MTS_PROC_COMPLETE
  [1] CONTEXT wo
0xB10 CORE_MMRS_RGX_CR_MTS_BGCTX_SBDATA0 ro
  [8:6] OS_ID — The OS_ID of the active thread
  [5] THREAD_ACTIVE — Indicates the thread is active
  [4] TASK
  [3:0] DM — DataMaster Type
0xB20 CORE_MMRS_RGX_CR_MTS_INTCTX_SBDATA0 ro
  [41:39] OS_ID — The OS_ID of the active thread
  [38] THREAD_ACTIVE — Indicates the thread is active
  [37:6] INT_STATUS — Interrupt Status for 32 event bus lines
  [5:2] DM — DataMaster Type
  [1:0] INT_TASK — Kick Request for timer/BG-request/host
0xB30 CORE_MMRS_RGX_CR_MTS_BGCTX_THREAD0_DM_ASSOC
  [15:0] DM_ASSOC rw — DataMaster Association [Active High]
0xB40 CORE_MMRS_RGX_CR_MTS_INTCTX_THREAD0_DM_ASSOC
  [15:0] DM_ASSOC rw — DataMaster Association [Active High]
0xB50 CORE_MMRS_RGX_CR_MTS_GARTEN_WRAPPER_CONFIG reset 0x1
  [0] IDLE_CTRL rw
{0xB58+8i} CORE_MMRS_RGX_CR_MTS_DM{i}_INTERRUPT_ENABLE (i=0..5)
  [31:0] INT_ENABLE rw — Interrupt Enable
0xB88 CORE_MMRS_RGX_CR_MTS_EVENT_MASK
  [31:0] MASK rw — DESCRIPTION
0xB90 CORE_MMRS_RGX_CR_MTS_EVENT_CLEAR
  [31:0] CLEAR wo — DESCRIPTION
0xB98 CORE_MMRS_RGX_CR_MTS_INTCTX ro
  [29:22] DM_HOST_SCHEDULE — A 1 bit counter per DM for host requests
  [15:8] DM_TIMER_SCHEDULE — A 1 bit counter per DM for timer requests
  [7:0] DM_INTERRUPT_SCHEDULE — A 1 bit counter per DM for interrupt requests
0xBA0 CORE_MMRS_RGX_CR_MTS_BGCTX ro
  [7:0] DM_NONCOUNTED_SCHEDULE — A 1 bit counter per DM for non-counted background request
0xBA8 CORE_MMRS_RGX_CR_MTS_BGCTX_COUNTED_SCHEDULE ro
  [8n+7:8n] DM{n} (n=0..5) — A 8 bit counter for DM{n}
0xBB0 CORE_MMRS_RGX_CR_MTS_GPU_INT_STATUS ro
  [31:0] STATUS — A 32 bit register for recored GPU events
0xBC0 CORE_MMRS_RGX_CR_MTS_OS_PRIORITY
  [2n+1:2n] ID{n} rw (n=0..7) — Scheduling priority for operating system {n}
0xBC8 CORE_MMRS_RGX_CR_MTS_SCHEDULE_ENABLE reset 0xFF
  [7:0] MASK rw
{0xBD8+0x10000*i} CORE_MMRS_RGX_CR_IRQ_OS{i}_EVENT_STATUS ro (i=0..7)
  [0] SOURCE
0xBE0 CORE_MMRS_RGX_CR_HOST_IRQ
  [2:0] OSID rw — Indicates the Guest OS for the interrupt
{0xBE8+0x10000*i} CORE_MMRS_RGX_CR_IRQ_OS{i}_EVENT_CLEAR (i=0..7)
  [0] SOURCE rw
0xBF8 CORE_MMRS_RGX_CR_META_BOOT
  [0] MODE rw — 0 = Don't boot, 1 = Boot
0xC00 CORE_MMRS_RGX_CR_TE_AA
  [3] Y2 rw — Indicates 4xmsaa when X2 and Y2 are set to 1. This does not affect TE and is only used within TPW.
  [2] Y rw — Anti-Aliasing in Y Plane Enabled
  [1] X rw — Anti-Aliasing in X Plane Enabled
  [0] X2 rw — 2x Anti-Aliasing Enabled, affects PPP only
0xC08 CORE_MMRS_RGX_CR_TE_MTILE1 reset 0x10100C
  [26:18] X1 rw — X1 MacroTile boundary, left tile X for second column of macrotiles [16MT mode] - 32 pixels across tile
  [17:9] X2 rw — X2 MacroTile boundary, left tile X for third[16MT] column of macrotiles - 32 pixels across tile
  [8:0] X3 rw — X3 MacroTile boundary, left tile X for fourth column of macrotiles [16MT] - 32 pixels across tile
